# DMPAC0_DMPAC_FOCO_0_CFG_SLV_DMPAC_FOCO_CORE_FOCO_REGS_CFG_IP_MMRS register map
Vendor: Texas Instruments
Peripheral module from a debugger description file (folder J7ES).
Registers are 32-bit, access per field, reset 0xFFFF0000 unless marked. A register's access mark holds for its fields unless they carry their own. Offsets are as the file gives them; lines under a group give offsets from that group; [hi:lo] are bit positions; {n}, {i} and the like mark numbered series; 'fields as' and 'values as' point back to an identical list; <NAME> marks a mode.

## DMPAC0_DMPAC_FOCO_0_CFG_SLV_DMPAC_FOCO_CORE_FOCO_REGS_CFG_IP_MMRS
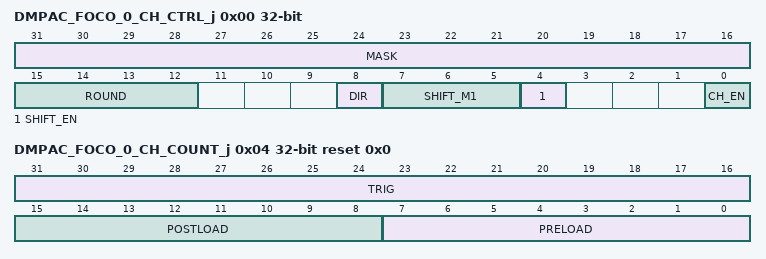
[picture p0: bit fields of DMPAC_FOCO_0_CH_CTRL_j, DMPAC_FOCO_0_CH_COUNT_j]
0x00 DMPAC_FOCO_0_CH_CTRL_j — Defines parameters that control the format conversion for input-output channel pair.
  [31:16] MASK rw — 16b mask value that will be and-ed with the result
  [15:12] ROUND rw — Unsigned Rounding value that will be added
  [8] DIR rw — Shift direction - left or right. 0 -&gt; Right. 1 -&gt; Left
  [7:5] SHIFT_M1 rw — Amount of bit shift minus 1.Valid values 0 to 7 meaning shift of 1 to 8. For no shift, configure SHIFT_EN to 0
  [4] SHIFT_EN rw — Enable for shifting. 0 --&gt; No shift. 1 --&gt; Shift determined by SHIFT_M1
  [0] CH_EN rw — Enable format conversion channel
0x04 DMPAC_FOCO_0_CH_COUNT_j rw reset 0x0 — Defines count values for pre/post load and functional operation for the format conversion for input-output channel pair.
  [31:16] TRIG — Defines the number of FOCO module operations (HTS starts/dones) for which the actual format conversion happens after PRELOAD number of FOCO module operations.This number cannot be 0 for an active channel
  [15:8] POSTLOAD — Defines the number of FOCO module operations (HTS starts/dones) that would be skipped after PRELOAD + TRIG number of FOCO module operations
  [7:0] PRELOAD — Defines the number of FOCO module operations (HTS starts/dones) that would be skipped after HTS init
